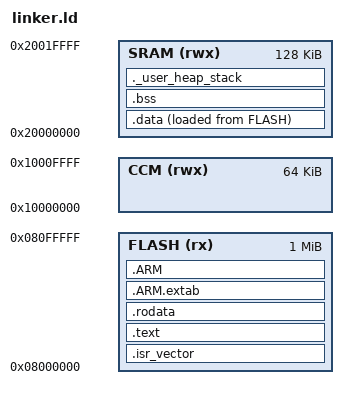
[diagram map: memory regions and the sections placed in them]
/* Linker Script for STM32F407 (Cortex-M4) */
/* Memory: 1MB Flash, 192KB SRAM */

ENTRY(Reset_Handler)

MEMORY
{
    FLASH (rx)  : ORIGIN = 0x08000000, LENGTH = 1024K
    SRAM (rwx)  : ORIGIN = 0x20000000, LENGTH = 128K
    CCM (rwx)   : ORIGIN = 0x10000000, LENGTH = 64K
}

/* Stack and heap sizes */
_Min_Heap_Size = 0x1000;   /* 4KB heap */
_Min_Stack_Size = 0x1000;  /* 4KB main stack */

SECTIONS
{
    /* Interrupt vector table - must be at start of flash */
    .isr_vector :
    {
        . = ALIGN(4);
        KEEP(*(.isr_vector))
        . = ALIGN(4);
    } > FLASH

    /* Code and read-only data */
    .text :
    {
        . = ALIGN(4);
        *(.text)
        *(.text*)
        *(.glue_7)
        *(.glue_7t)
        *(.eh_frame)

        KEEP(*(.init))
        KEEP(*(.fini))

        . = ALIGN(4);
        _etext = .;
    } > FLASH

    /* Constant data */
    .rodata :
    {
        . = ALIGN(4);
        *(.rodata)
        *(.rodata*)
        . = ALIGN(4);
    } > FLASH

    /* ARM exception handling */
    .ARM.extab :
    {
        *(.ARM.extab* .gnu.linkonce.armextab.*)
    } > FLASH

    .ARM :
    {
        __exidx_start = .;
        *(.ARM.exidx*)
        __exidx_end = .;
    } > FLASH

    /* Used by startup to initialize data */
    _sidata = LOADADDR(.data);

    /* Initialized data - loaded to flash, copied to RAM */
    .data :
    {
        . = ALIGN(4);
        _sdata = .;
        *(.data)
        *(.data*)
        . = ALIGN(4);
        _edata = .;
    } > SRAM AT > FLASH

    /* Uninitialized data - zeroed by startup */
    .bss :
    {
        . = ALIGN(4);
        _sbss = .;
        __bss_start__ = _sbss;
        *(.bss)
        *(.bss*)
        *(COMMON)
        . = ALIGN(4);
        _ebss = .;
        __bss_end__ = _ebss;
    } > SRAM

    /* User heap */
    ._user_heap_stack :
    {
        . = ALIGN(8);
        PROVIDE(end = .);
        PROVIDE(_end = .);
        . = . + _Min_Heap_Size;
        . = . + _Min_Stack_Size;
        . = ALIGN(8);
    } > SRAM

    /* Main stack at end of SRAM */
    _estack = ORIGIN(SRAM) + LENGTH(SRAM);

    /* Discard unwanted sections */
    /DISCARD/ :
    {
        libc.a(*)
        libm.a(*)
        libgcc.a(*)
    }

    /* ARM attributes */
    .ARM.attributes 0 : { *(.ARM.attributes) }
}
